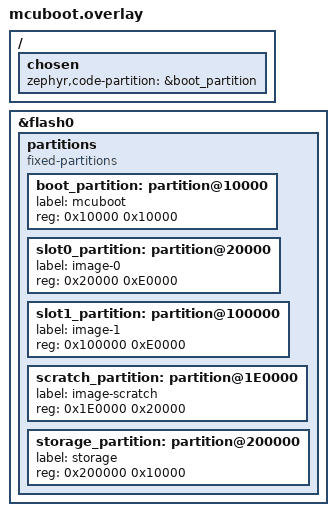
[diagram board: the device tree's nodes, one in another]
/*
 * This overlay is for the MCUboot bootloader domain.
 * It defines the complete flash partition map and tells MCUboot
 * where its own code is located.
 */

/ {
    chosen {
        /*
         * This tells Zephyr that the bootloader's own code is in
         * the partition labeled 'mcuboot', which we name 'boot_partition'.
         */
        zephyr,code-partition = &boot_partition;
    };
};

&flash0 {
    /*
     * We define a completely new set of partitions, tailored for MCUboot
     * in swap-scratch mode.
     */
    /delete-node/ partitions;
    partitions {
        compatible = "fixed-partitions";
        #address-cells = <1>;
        #size-cells = <1>;

        /* Partition for the bootloader itself. Starts at 64K offset. */
        boot_partition: partition@10000 {
            label = "mcuboot";
            reg = <0x10000 0x10000>; /* 64 KB */
        };

        /* Primary application slot. */
        slot0_partition: partition@20000 {
            label = "image-0";
            reg = <0x20000 0xE0000>; /* 896 KB */
        };

        /* Secondary application slot (for the update). */
        slot1_partition: partition@100000 {
            label = "image-1";
            reg = <0x100000 0xE0000>; /* 896 KB */
        };

        /* Scratch partition for swapping images. Label is critical! */
        scratch_partition: partition@1E0000 {
            label = "image-scratch"; /* MUST be "image-scratch" for Kconfig */
            reg = <0x1E0000 0x20000>;  /* 128 KB */
        };

        /* Optional partition for a file system or other data. */
        storage_partition: partition@200000 {
            label = "storage";
            reg = <0x200000 0x10000>; /* 64 KB */
        };
    };
};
